# ime5_target_db register map
Vendor: Texas Instruments
Peripheral module from a debugger description file (folder iva2_arp32).
Address unit: 16 bits
Registers are 32-bit, access per field, reset 0x0 unless marked. A register's access mark holds for its fields unless they carry their own. Offsets are as the file gives them; lines under a group give offsets from that group; [hi:lo] are bit positions; {n}, {i} and the like mark numbered series; 'fields as' and 'values as' point back to an identical list; <NAME> marks a mode.

## IME5 (part 1 of 3) — ipxact12_to_ccs_generated
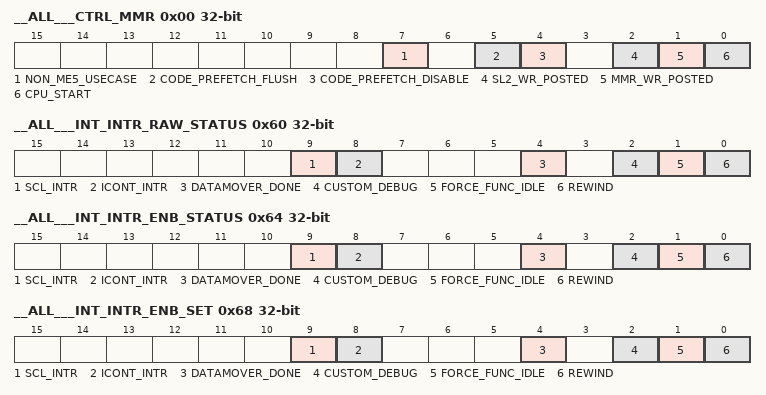
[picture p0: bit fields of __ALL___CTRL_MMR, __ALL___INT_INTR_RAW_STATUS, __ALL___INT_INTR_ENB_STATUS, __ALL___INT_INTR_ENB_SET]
0x00 __ALL___CTRL_MMR — Holds the various system control registers.
  [7] NON_ME5_USECASE rw — Set to 1 to indicate Non ME5 usecase. In this mode, the HW engines for motion estimation will not be usable. Set to 0 for ME5 usecase. In this mode, the HW engines for motion estimation are active. The Host config master interface will not be usable. In other words, in this mode, ME5 cpu will not be able to write/read MMR/config registers that are external to ME5. SL2 data can still be accessed.
  [5] CODE_PREFETCH_FLUSH rw — Flush code prefetch from SL2 space. Auto cleared to 0.
  [4] CODE_PREFETCH_DISABLE rw — Disable code prefetch from SL2 space.
  [2] SL2_WR_POSTED rw — When set, Posted SL2 writes from CPU will be enabled. When cleared, all SL2 writes from CPU are performed as non-posted writes.
  [1] MMR_WR_POSTED rw — When set, Posted MMR writes from CPU will be enabled. When cleared, all MMR writes from CPU are performed as non-posted writes.
  [0] CPU_START rw — When Set, Indicates that ME5 CPU is enabled to execute (out of reset). When low, indicates that ME5 CPU is in reset. (When low, it should remain low for atleast 4 clock period to reset cpu)
0x04 __ALL___ME5_INTR_OUTPUT rw — Generates interrupt to SCL module. Corresponding bitfield is to be set to generate interrupt. The bitfield is self cleared on generating interrupt.
  [0] SCL_INTR — Generates Interrupt to Scalar.
0x40 __ALL___DM_SRC rw — DataMover Units Source Address register. Address should be a multiple of 4.
  [31:0] SRC — Specifies the data Source.
0x44 __ALL___DM_DST rw — DataMover units Destination Address register. Address should be a multiple of 4.
  [31:0] DST — Specifies the data Destination.
0x48 __ALL___DM_ByteCnt — DataMover units ByteCount register. Specifies the number of bytes to be transfered from Source address to Destination address. This should be a mulyiple of 4. Write to this register triggers data transfer.
  [15:0] ByteCount rw — Specifies the size of data transfer (in Bytes).
0x60 __ALL___INT_INTR_RAW_STATUS rw — This provides the status of the interrupt sources generating interrupt to ME5-ARP32, irrespective of enable bit. Write 1 to set the interrupt in Software (for test/debug).
  [9] SCL_INTR — Interrupt from SCL.
  [8] ICONT_INTR — Interrupt from ICONT.
  [4] DATAMOVER_DONE — DataMover transfer completion.
  [2] CUSTOM_DEBUG — Custom Debug event detected by HW.
  [1] FORCE_FUNC_IDLE — Abort or channel switch after rewind condition.
  [0] REWIND — Rewind process complete.
0x64 __ALL___INT_INTR_ENB_STATUS rw — This provides the status of the interrupt sources generating interrupt to ICONT, enabled to interrupt. Write 1 to clear the interrupt in Software.
  fields as __ALL___INT_INTR_RAW_STATUS
0x68 __ALL___INT_INTR_ENB_SET rw — Enables the corresponding interrupt source to generate interrupt to ICONT. Write 1 to set the corresponding interrupt enable bit.
  fields as __ALL___INT_INTR_RAW_STATUS
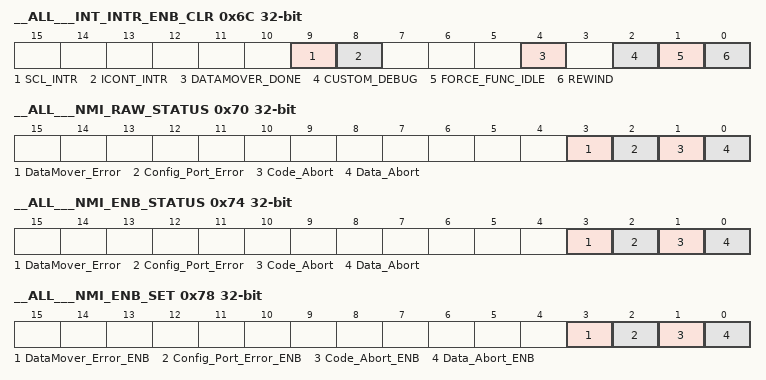
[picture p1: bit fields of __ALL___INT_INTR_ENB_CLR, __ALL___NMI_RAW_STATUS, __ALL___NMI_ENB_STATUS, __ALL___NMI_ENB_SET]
0x6C __ALL___INT_INTR_ENB_CLR rw — Enables the corresponding interrupt source to generate interrupt to ICONT. Write 1 to Clear the corresponding interrupt enable bit.
  fields as __ALL___INT_INTR_RAW_STATUS
0x70 __ALL___NMI_RAW_STATUS — This provides the status of the ICONT NMI sources, irrespective of enable bit. Write 1 to set the interrupt in Software (for test/debug).
  [3] DataMover_Error rw — Indicates if the previous data transfer completed with an ocp error.
  [2] Config_Port_Error rw — Indicates error response on Config master port.
  [1] Code_Abort rw — CPU Code access to Reserved space. ICONT_NMI_ABORT_ADDR logs the access address.
  [0] Data_Abort rw — CPU data access to Reserved space. ICONT_NMI_ABORT_ADDR logs the access address.
0x74 __ALL___NMI_ENB_STATUS — This provides the status of the ICONT NMI interrupt sources enabled to interrupt. Write 1 to clear the interrupt in Software.
  [3] DataMover_Error rw — Indicates if the previous data transfer completed with an ocp error.
  [2] Config_Port_Error rw — Indicates error response on Config master port.
  [1] Code_Abort rw — CPU code access to Reserved space. ICONT_NMI_ABORT_ADDR logs the access address.
  [0] Data_Abort rw — CPU data access to Reserved space. ICONT_NMI_ABORT_ADDR logs the access address.
0x78 __ALL___NMI_ENB_SET — Enables the corresponding interrupt source to generate interrupt. Write 1 to set the corresponding interrupt enable bit.
  [3] DataMover_Error_ENB rw — Indicates if the previous data transfer completed with an ocp error.
  [2] Config_Port_Error_ENB rw
  [1] Code_Abort_ENB rw
  [0] Data_Abort_ENB rw
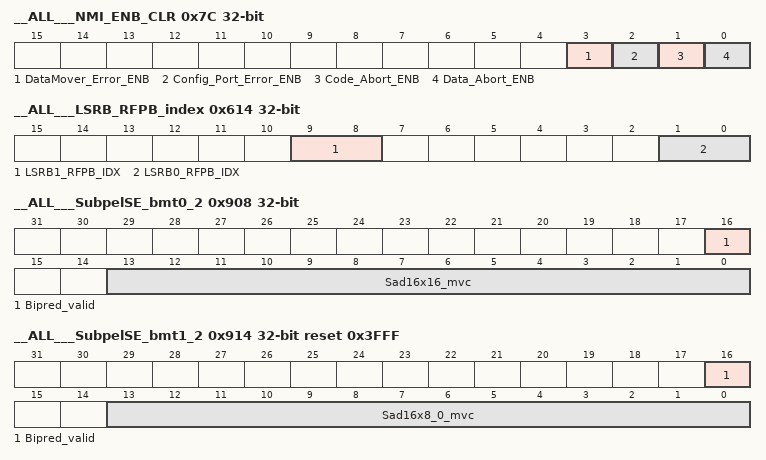
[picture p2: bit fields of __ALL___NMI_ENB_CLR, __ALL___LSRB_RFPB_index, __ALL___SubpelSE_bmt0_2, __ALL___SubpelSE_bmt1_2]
0x7C __ALL___NMI_ENB_CLR — Enables the corresponding interrupt source to generate interrupt. Write 1 to Clear the corresponding interrupt enable bit.
  fields as __ALL___NMI_ENB_SET
0x80 __ALL___NMI_ABORT_ADDR ro — Logs the Address that resulted in the T16Core Data or Code abort condition.
  [31:0] Address
0x100 __ALL___PSE_bmt0_0 rw — This register contains motion vector for best 16x16 partition
  [31:0] mvy_mvx — Motion vector
0x104 __ALL___PSE_bmt0_1 reset 0xFFFF — This register contains SAD for best 16x16 partition
  [15:0] Sad16x16 rw — SAD Value
0x108 __ALL___PSE_bmt0_2 — This register contains Motion Vector Cost for best 16x16 partition
  [13:0] Sad16x16_mvc rw — Motion vector Cost
0x10C __ALL___PSE_bmt1_0 rw — This register contains motion vector for best top 16x8 partition
  [31:0] mvy_mvx — Motion vector
0x110 __ALL___PSE_bmt1_1 reset 0xFFFF — This register contains SAD for best top 16x8 partition
  [15:0] Sad16x8_0 rw — SAD Value
0x114 __ALL___PSE_bmt1_2 reset 0x3FFF
  [13:0] Sad16x8_0_mvc rw — Motion vector Cost
0x118 __ALL___PSE_bmt2_0 rw — This register contains motion vector for best bottom 16x8 partition
  [31:0] mvy_mvx — Motion vector
0x11C __ALL___PSE_bmt2_1 reset 0xFFFF — This register contains SAD for best bottom 16x8 partition
  [15:0] Sad16x8_1 rw — SAD Value
0x120 __ALL___PSE_bmt2_2 reset 0x3FFF
  [13:0] Sad16x8_1_mvc rw — Motion vector Cost
0x124 __ALL___PSE_bmt3_0 rw — This register contains motion vector for best left 8x16 partition
  [31:0] mvy_mvx — Motion vector
0x128 __ALL___PSE_bmt3_1 reset 0xFFFF — This register contains SAD for best left 8x16 partition
  [15:0] Sad8x16_0 rw — SAD Value
0x12C __ALL___PSE_bmt3_2 reset 0x3FFF
  [13:0] Sad8x16_0_mvc rw — Motion vector Cost
0x130 __ALL___PSE_bmt4_0 rw — This register contains motion vector for best right 8x16 partition
  [31:0] mvy_mvx — Motion vector
0x134 __ALL___PSE_bmt4_1 reset 0xFFFF — This register contains SAD for best right 8x16 partition
  [15:0] Sad8x16_1 rw — SAD Value
0x138 __ALL___PSE_bmt4_2 reset 0x3FFF
  [13:0] Sad8x16_1_mvc rw — Motion vector Cost
0x13C __ALL___PSE_bmt5_0 rw — This register contains motion vector for best top left 8x8 partition
  [31:0] mvy_mvx — Motion vector
0x140 __ALL___PSE_bmt5_1 reset 0xFFFF — This register contains SAD for best top left 8x8 partition
  [15:0] Sad8x8_0 rw — SAD Value
{0x108+0xC*i} __ALL___PSE_bmt{i}_2 reset 0x3FFF (i=5..8)
  [13:0] Sad8x8_{i-5}_mvc rw — Motion vector Cost
0x148 __ALL___PSE_bmt6_0 rw — This register contains motion vector for best top right 8x8 partition
  [31:0] mvy_mvx — Motion vector
0x14C __ALL___PSE_bmt6_1 reset 0xFFFF — This register contains SAD for best top right 8x8 partition
  [15:0] Sad8x8_1 rw — SAD Value
0x154 __ALL___PSE_bmt7_0 rw — This register contains motion vector for best bottom leftt 8x8 partition
  [31:0] mvy_mvx — Motion vector
0x158 __ALL___PSE_bmt7_1 reset 0xFFFF — This register contains SAD for best bottom leftt 8x8 partition
  [15:0] Sad8x8_2 rw — SAD Value
0x160 __ALL___PSE_bmt8_0 rw — This register contains motion vector for best bottomright 8x8 partition
  [31:0] mvy_mvx — Motion vector
0x164 __ALL___PSE_bmt8_1 reset 0xFFFF — This register contains SAD for best bottomright 8x8 partition
  [15:0] Sad8x8_3 rw — SAD Value
{0x100+0xC*i} __ALL___PSE_bmt{i}_0 rw (i=9..11) — This register contains motion vector for best next best 16x16 partition
  [31:0] mvy_mvx — Motion vector
{0x104+0xC*i} __ALL___PSE_bmt{i}_1 reset 0xFFFF (i=9..11) — This register contains SAD for best next best 16x16 partition
  [15:0] Sad16x16_{i-8} rw — SAD Value
{0x108+0xC*i} __ALL___PSE_bmt{i}_2 reset 0x3FFF (i=9..11)
  [13:0] Sad16x16_{i-8}_mvc rw — Motion vector Cost
0x200 __ALL___PSE_SHADOWbmt0_0 rw — This register contains motion vector for best 16x16 partition
  [31:0] mvy_mvx — Motion vector
0x204 __ALL___PSE_SHADOWbmt0_1 reset 0xFFFF — This register contains SAD for best 16x16 partition
  [15:0] Sad16x16 rw — SAD Value
0x208 __ALL___PSE_SHADOWbmt0_2 — This register contains Motion Vector Cost for best 16x16 partition
  [13:0] Sad16x16_mvc rw — Motion vector Cost
0x20C __ALL___PSE_SHADOWbmt1_0 rw — This register contains motion vector for best top 16x8 partition
  [31:0] mvy_mvx — Motion vector
0x210 __ALL___PSE_SHADOWbmt1_1 reset 0xFFFF — This register contains SAD for best top 16x8 partition
  [15:0] Sad16x8_0 rw — SAD Value
0x214 __ALL___PSE_SHADOWbmt1_2 reset 0x3FFF
  [13:0] Sad16x8_0_mvc rw — Motion vector Cost
0x218 __ALL___PSE_SHADOWbmt2_0 rw — This register contains motion vector for best bottom 16x8 partition
  [31:0] mvy_mvx — Motion vector
0x21C __ALL___PSE_SHADOWbmt2_1 reset 0xFFFF — This register contains SAD for best bottom 16x8 partition
  [15:0] Sad16x8_1 rw — SAD Value
0x220 __ALL___PSE_SHADOWbmt2_2 reset 0x3FFF
  [13:0] Sad16x8_1_mvc rw — Motion vector Cost
0x224 __ALL___PSE_SHADOWbmt3_0 rw — This register contains motion vector for best left 8x16 partition
  [31:0] mvy_mvx — Motion vector
0x228 __ALL___PSE_SHADOWbmt3_1 reset 0xFFFF — This register contains SAD for best left 8x16 partition
  [15:0] Sad8x16_0 rw — SAD Value
0x22C __ALL___PSE_SHADOWbmt3_2 reset 0x3FFF
  [13:0] Sad8x16_0_mvc rw — Motion vector Cost
0x230 __ALL___PSE_SHADOWbmt4_0 rw — This register contains motion vector for best right 8x16 partition
  [31:0] mvy_mvx — Motion vector
0x234 __ALL___PSE_SHADOWbmt4_1 reset 0xFFFF — This register contains SAD for best right 8x16 partition
  [15:0] Sad8x16_1 rw — SAD Value
0x238 __ALL___PSE_SHADOWbmt4_2 reset 0x3FFF
  [13:0] Sad8x16_1_mvc rw — Motion vector Cost
0x23C __ALL___PSE_SHADOWbmt5_0 rw — This register contains motion vector for best top left 8x8 partition
  [31:0] mvy_mvx — Motion vector
0x240 __ALL___PSE_SHADOWbmt5_1 reset 0xFFFF — This register contains SAD for best top left 8x8 partition
  [15:0] Sad8x8_0 rw — SAD Value
{0x208+0xC*i} __ALL___PSE_SHADOWbmt{i}_2 reset 0x3FFF (i=5..8)
  [13:0] Sad8x8_{i-5}_mvc rw — Motion vector Cost
0x248 __ALL___PSE_SHADOWbmt6_0 rw — This register contains motion vector for best top right 8x8 partition
  [31:0] mvy_mvx — Motion vector
0x24C __ALL___PSE_SHADOWbmt6_1 reset 0xFFFF — This register contains SAD for best top right 8x8 partition
  [15:0] Sad8x8_1 rw — SAD Value
0x254 __ALL___PSE_SHADOWbmt7_0 rw — This register contains motion vector for best bottom leftt 8x8 partition
  [31:0] mvy_mvx — Motion vector
0x258 __ALL___PSE_SHADOWbmt7_1 reset 0xFFFF — This register contains SAD for best bottom leftt 8x8 partition
  [15:0] Sad8x8_2 rw — SAD Value
0x260 __ALL___PSE_SHADOWbmt8_0 rw — This register contains motion vector for best bottomright 8x8 partition
  [31:0] mvy_mvx — Motion vector
0x264 __ALL___PSE_SHADOWbmt8_1 reset 0xFFFF — This register contains SAD for best bottomright 8x8 partition
  [15:0] Sad8x8_3 rw — SAD Value
{0x200+0xC*i} __ALL___PSE_SHADOWbmt{i}_0 rw (i=9..11) — This register contains motion vector for best next best 16x16 partition
  [31:0] mvy_mvx — Motion vector
{0x204+0xC*i} __ALL___PSE_SHADOWbmt{i}_1 reset 0xFFFF (i=9..11) — This register contains SAD for best next best 16x16 partition
  [15:0] Sad16x16_{i-8} rw — SAD Value
{0x208+0xC*i} __ALL___PSE_SHADOWbmt{i}_2 reset 0x3FFF (i=9..11)
  [13:0] Sad16x16_{i-8}_mvc rw — Motion vector Cost
0x500 __ALL___VSE_bmt0_0 rw — This register contains motion vector for best 16x16 partition
  [31:0] mvy_mvx — Motion vector
0x504 __ALL___VSE_bmt0_1 reset 0xFFFF — This register contains SAD for best 16x16 partition
  [15:0] Sad16x16 rw — SAD Value
0x508 __ALL___VSE_bmt0_2 — This register contains Motion Vector Cost for best 16x16 partition
  [13:0] Sad16x16_mvc rw — Motion vector Cost
0x50C __ALL___VSE_bmt1_0 rw — This register contains motion vector for best top 16x8 partition
  [31:0] mvy_mvx — Motion vector
0x510 __ALL___VSE_bmt1_1 reset 0xFFFF — This register contains SAD for best top 16x8 partition
  [15:0] Sad16x8_0 rw — SAD Value
0x514 __ALL___VSE_bmt1_2 reset 0x3FFF
  [13:0] Sad16x8_0_mvc rw — Motion vector Cost
0x518 __ALL___VSE_bmt2_0 rw — This register contains motion vector for best bottom 16x8 partition
  [31:0] mvy_mvx — Motion vector
0x51C __ALL___VSE_bmt2_1 reset 0xFFFF — This register contains SAD for best bottom 16x8 partition
  [15:0] Sad16x8_1 rw — SAD Value
0x520 __ALL___VSE_bmt2_2 reset 0x3FFF
  [13:0] Sad16x8_1_mvc rw — Motion vector Cost
0x524 __ALL___VSE_bmt3_0 rw — This register contains motion vector for best left 8x16 partition
  [31:0] mvy_mvx — Motion vector
0x528 __ALL___VSE_bmt3_1 reset 0xFFFF — This register contains SAD for best left 8x16 partition
  [15:0] Sad8x16_0 rw — SAD Value
0x52C __ALL___VSE_bmt3_2 reset 0x3FFF
  [13:0] Sad8x16_0_mvc rw — Motion vector Cost
0x530 __ALL___VSE_bmt4_0 rw — This register contains motion vector for best right 8x16 partition
  [31:0] mvy_mvx — Motion vector
0x534 __ALL___VSE_bmt4_1 reset 0xFFFF — This register contains SAD for best right 8x16 partition
  [15:0] Sad8x16_1 rw — SAD Value
0x538 __ALL___VSE_bmt4_2 reset 0x3FFF
  [13:0] Sad8x16_1_mvc rw — Motion vector Cost
0x53C __ALL___VSE_bmt5_0 rw — This register contains motion vector for best top left 8x8 partition
  [31:0] mvy_mvx — Motion vector
0x540 __ALL___VSE_bmt5_1 reset 0xFFFF — This register contains SAD for best top left 8x8 partition
  [15:0] Sad8x8_0 rw — SAD Value
{0x508+0xC*i} __ALL___VSE_bmt{i}_2 reset 0x3FFF (i=5..8)
  [13:0] Sad8x8_{i-5}_mvc rw — Motion vector Cost
0x548 __ALL___VSE_bmt6_0 rw — This register contains motion vector for best top right 8x8 partition
  [31:0] mvy_mvx — Motion vector
0x54C __ALL___VSE_bmt6_1 reset 0xFFFF — This register contains SAD for best top right 8x8 partition
  [15:0] Sad8x8_1 rw — SAD Value
0x554 __ALL___VSE_bmt7_0 rw — This register contains motion vector for best bottom leftt 8x8 partition
  [31:0] mvy_mvx — Motion vector
0x558 __ALL___VSE_bmt7_1 reset 0xFFFF — This register contains SAD for best bottom leftt 8x8 partition
  [15:0] Sad8x8_2 rw — SAD Value
0x560 __ALL___VSE_bmt8_0 rw — This register contains motion vector for best bottomright 8x8 partition
  [31:0] mvy_mvx — Motion vector
0x564 __ALL___VSE_bmt8_1 reset 0xFFFF — This register contains SAD for best bottomright 8x8 partition
  [15:0] Sad8x8_3 rw — SAD Value
{0x500+0xC*i} __ALL___VSE_bmt{i}_0 rw (i=9..14) — This register contains motion vector for best next best 16x16 partition
  [31:0] mvy_mvx — Motion vector
{0x504+0xC*i} __ALL___VSE_bmt{i}_1 reset 0xFFFF (i=9..14) — This register contains SAD for best next best 16x16 partition
  [15:0] Sad16x16_{i-8} rw — SAD Value
{0x508+0xC*i} __ALL___VSE_bmt{i}_2 reset 0x3FFF (i=9..14)
  [13:0] Sad16x16_{i-8}_mvc rw — Motion vector Cost
0x5B4 __ALL___VSE_SC_Extra rw — Additional Search centre register
  [31:0] mvy_mvx — Motion vector
0x600 __ALL___LSRB0_Base rw — LSRB0 Base address
  [31:0] mvy_mvx — Motion vector
0x604 __ALL___LSRB1_Base rw reset 0x1 — LSRB1 Base address
  [31:0] mvy_mvx — Motion vector
0x608 __ALL___LSRB0_Valid_offsets ro (reset mask 0xC0C0C0C0) — LSRB0 Valid offset for valid area checks
0x60C __ALL___LSRB1_Valid_offsets ro (reset mask 0xC0C0C0C0) — LSRB1 Valid offset for valid area checks
0x610 __ALL___LSRB_reference_mv rw — LSRB reference motion vector for load lsrb
  [31:0] mvy_mvx — Motion vector
0x614 __ALL___LSRB_RFPB_index — LSRB_RFPB_index
  [9:8] LSRB1_RFPB_IDX rw, [1:0] LSRB0_RFPB_IDX rw
0x900 __ALL___SubpelSE_bmt0_0 rw — This register contains motion vector for best 16x16 partition
  [31:0] mvy_mvx — Motion vector
0x904 __ALL___SubpelSE_bmt0_1 reset 0xFFFF — This register contains SAD for best 16x16 partition
  [16:0] Sad16x16 rw — SAD Value
0x908 __ALL___SubpelSE_bmt0_2 — This register contains Motion Vector Cost for best 16x16 partition
  [16] Bipred_valid rw — Bipred valid bit
  [13:0] Sad16x16_mvc rw — Motion vector Cost
0x90C __ALL___SubpelSE_bmt1_0 rw — This register contains motion vector for best top 16x8 partition
  [31:0] mvy_mvx — Motion vector
0x910 __ALL___SubpelSE_bmt1_1 reset 0xFFFF — This register contains SAD for best top 16x8 partition
  [16:0] Sad16x8_0 rw — SAD Value
0x914 __ALL___SubpelSE_bmt1_2 reset 0x3FFF — This register contains Motion Vector Cost for best top 16x8 partition
  [16] Bipred_valid rw — Bipred valid bit
  [13:0] Sad16x8_0_mvc rw — Motion vector Cost
0x918 __ALL___SubpelSE_bmt2_0 rw — This register contains motion vector for best bottom 16x8 partition
  [31:0] mvy_mvx — Motion vector
0x91C __ALL___SubpelSE_bmt2_1 reset 0xFFFF — This register contains SAD for best bottom 16x8 partition
  [16:0] Sad16x8_1 rw — SAD Value
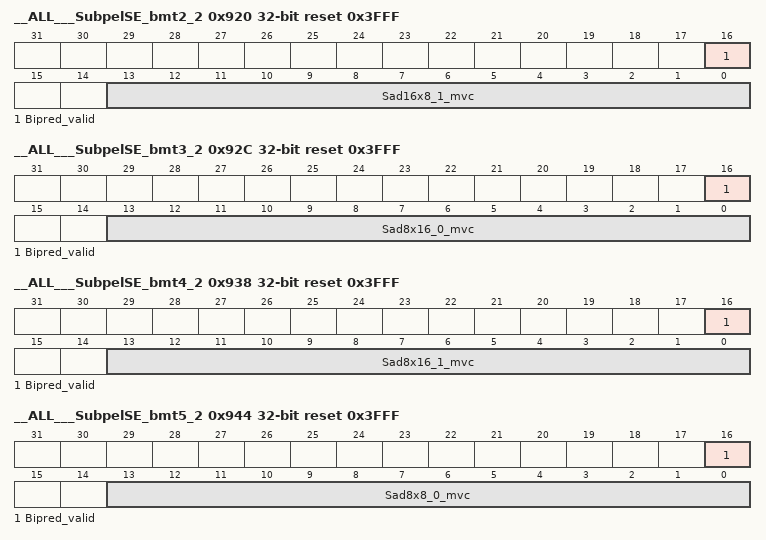
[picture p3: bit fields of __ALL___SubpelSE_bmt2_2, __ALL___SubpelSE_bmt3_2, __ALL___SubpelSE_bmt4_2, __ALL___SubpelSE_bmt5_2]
0x920 __ALL___SubpelSE_bmt2_2 reset 0x3FFF — This register contains Motion Vector Cost for best bottom 16x8 partition
  [16] Bipred_valid rw — Bipred valid bit
  [13:0] Sad16x8_1_mvc rw — Motion vector Cost
0x924 __ALL___SubpelSE_bmt3_0 rw — This register contains motion vector for best left 8x16 partition
  [31:0] mvy_mvx — Motion vector
0x928 __ALL___SubpelSE_bmt3_1 reset 0xFFFF — This register contains SAD for best left 8x16 partition
  [16:0] Sad8x16_0 rw — SAD Value
0x92C __ALL___SubpelSE_bmt3_2 reset 0x3FFF — This register contains Motion Vector Cost for best left 8x16 partition
  [16] Bipred_valid rw — Bipred valid bit
  [13:0] Sad8x16_0_mvc rw — Motion vector Cost
0x930 __ALL___SubpelSE_bmt4_0 rw — This register contains motion vector for best right 8x16 partition
  [31:0] mvy_mvx — Motion vector
0x934 __ALL___SubpelSE_bmt4_1 reset 0xFFFF — This register contains SAD for best right 8x16 partition
  [16:0] Sad8x16_1 rw — SAD Value
0x938 __ALL___SubpelSE_bmt4_2 reset 0x3FFF — This register contains Motion Vector Cost for best right 8x16 partition
  [16] Bipred_valid rw — Bipred valid bit
  [13:0] Sad8x16_1_mvc rw — Motion vector Cost
0x93C __ALL___SubpelSE_bmt5_0 rw — This register contains motion vector for best top left 8x8 partition
  [31:0] mvy_mvx — Motion vector
0x940 __ALL___SubpelSE_bmt5_1 reset 0xFFFF — This register contains SAD for best top left 8x8 partition
  [16:0] Sad8x8_0 rw — SAD Value
0x944 __ALL___SubpelSE_bmt5_2 reset 0x3FFF — This register contains Motion Vector Cost for best top left 8x8 partition
  [16] Bipred_valid rw — Bipred valid bit
  [13:0] Sad8x8_0_mvc rw — Motion vector Cost
0x948 __ALL___SubpelSE_bmt6_0 rw — This register contains motion vector for best top right 8x8 partition
  [31:0] mvy_mvx — Motion vector
0x94C __ALL___SubpelSE_bmt6_1 reset 0xFFFF — This register contains SAD for best top right 8x8 partition
  [16:0] Sad8x8_1 rw — SAD Value
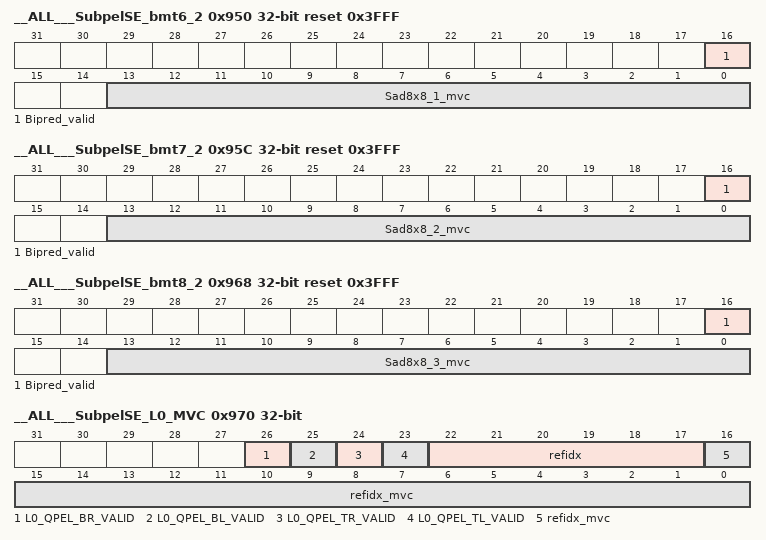
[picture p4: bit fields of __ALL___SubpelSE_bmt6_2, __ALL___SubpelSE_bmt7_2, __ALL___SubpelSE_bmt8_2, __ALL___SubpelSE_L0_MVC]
0x950 __ALL___SubpelSE_bmt6_2 reset 0x3FFF — This register contains Motion Vector Cost for best top right 8x8 partition
  [16] Bipred_valid rw — Bipred valid bit
  [13:0] Sad8x8_1_mvc rw — Motion vector Cost
0x954 __ALL___SubpelSE_bmt7_0 rw — This register contains motion vector for best bottom leftt 8x8 partition
  [31:0] mvy_mvx — Motion vector
0x958 __ALL___SubpelSE_bmt7_1 reset 0xFFFF — This register contains SAD for best bottom leftt 8x8 partition
  [16:0] Sad8x8_2 rw — SAD Value
0x95C __ALL___SubpelSE_bmt7_2 reset 0x3FFF — This register contains Motion Vector Cost for best bottom leftt 8x8 partition
  [16] Bipred_valid rw — Bipred valid bit
  [13:0] Sad8x8_2_mvc rw — Motion vector Cost
0x960 __ALL___SubpelSE_bmt8_0 rw — This register contains motion vector for best bottomright 8x8 partition
  [31:0] mvy_mvx — Motion vector
0x964 __ALL___SubpelSE_bmt8_1 reset 0xFFFF — This register contains SAD for best bottomright 8x8 partition
  [16:0] Sad8x8_3 rw — SAD Value
0x968 __ALL___SubpelSE_bmt8_2 reset 0x3FFF — This register contains Motion Vector Cost for best bottomright 8x8 partition
  [16] Bipred_valid rw — Bipred valid bit
  [13:0] Sad8x8_3_mvc rw — Motion vector Cost
0x96C __ALL___SubpelSE_L0_MV rw — This register contains motion vector of winner q-pel plane
  [31:0] mvy_mvx — Motion vector
0x970 __ALL___SubpelSE_L0_MVC — This register contains motion vector of winner q-pel plane motion vector
  [26] L0_QPEL_BR_VALID rw — L0 MV is valid
  [25] L0_QPEL_BL_VALID rw — L0 MV is valid
  [24] L0_QPEL_TR_VALID rw — L0 MV is valid
  [23] L0_QPEL_TL_VALID rw — L0 MV is valid
  [22:17] refidx rw — LO referecne Idx
  [16:0] refidx_mvc rw — Motion vector Cost
0x974 __ALL___HPEL_SC_EXTRA rw — This register contains motion vector of search centre for hpel calculation
  [31:0] mvy_mvx — Motion vector
0x978 __ALL___QPEL_SC_EXTRA rw — This register contains motion vector of search centre for qpel calculation
  [31:0] mvy_mvx — Motion vector
0x97C __ALL___WINNER_MV_STATS rw — This register contains motion vector after Qpel for Statistic collection
  [31:0] mvy_mvx — Motion vector for Statistic collection. Updated after searchQpel instruction if the update_statistics flag is set. This motion vector will be used for updating the statistics during write output instruction. Also note that USE_FOR_MVSTAT in RF_CTRL_REG0_RFPB1 should also be set for this register to be updated.
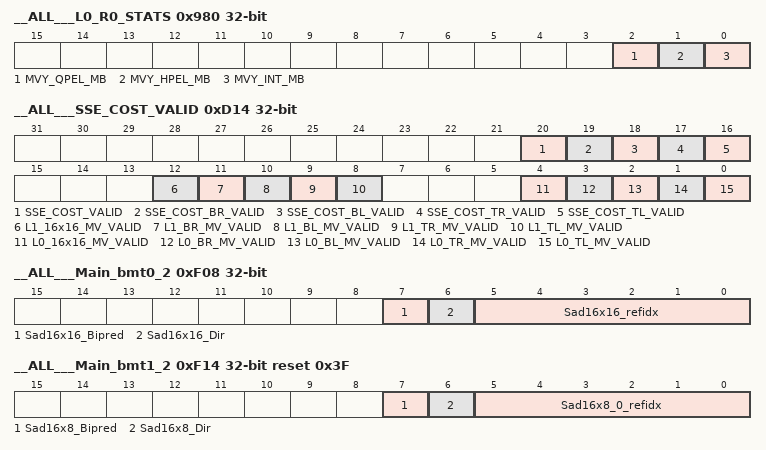
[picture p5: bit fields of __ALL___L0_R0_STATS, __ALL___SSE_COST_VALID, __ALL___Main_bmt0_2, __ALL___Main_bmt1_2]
0x980 __ALL___L0_R0_STATS rw — This register contains Statistics information for winner L0 R0 motion vector
  [2] MVY_QPEL_MB — This bit field set when L0 R0 winner motion vector's Y component is QPEL. This bit is updated only after searchQpel instruction if the update_statistics flag is set. Note that this bit is updated only during L0 direction and when the reference index is 0
  [1] MVY_HPEL_MB — This bit field set when L0 R0 winner motion vector's Y component is HPEL. This bit is updated only after searchQpel instruction if the update_statistics flag is set. Note that this bit is updated only during L0 direction and when the reference index is 0
  [0] MVY_INT_MB — This bit field set when L0 R0 winner motion vector's Y component is integer. This bit is updated only after searchQpel instruction if the update_statistics flag is set. Note that this bit is updated only during L0 direction and when the reference index is 0
0xD00 __ALL___SSE_Cost16x16 reset 0xFFFF — This register contains cost of 16x16 partition at skip mv position
  [15:0] SSE_Cost16x16 rw — 16x16 SAD cost
0xD04 __ALL___SSE_Cost_TL8x8 reset 0x3FFF — This register contains cost of TL 8x8 partition at skip mv position
  [13:0] SSE_Cost_TL8x8 rw — 8x8 TL SAD cost
0xD08 __ALL___SSE_Cost_TR8x8 reset 0x3FFF — This register contains cost of TR 8x8 partition at skip mv position
  [13:0] SSE_Cost_TR8x8 rw — 8x8 TR SAD cost
0xD0C __ALL___SSE_Cost_BL8x8 reset 0x3FFF — This register contains cost of BL 8x8 partition at skip mv position
  [13:0] SSE_Cost_BL8x8 rw — 8x8 BL SAD cost
0xD10 __ALL___SSE_Cost_BR8x8 reset 0x3FFF — This register contains cost of BR 8x8 partition at skip mv position
  [13:0] SSE_Cost_BR8x8 rw — 8x8 BR SAD cost
0xD14 __ALL___SSE_COST_VALID — This register contains valid bits for debug
  [20] SSE_COST_VALID rw
  [19] SSE_COST_BR_VALID rw — SSE cost valid
  [18] SSE_COST_BL_VALID rw — SSE cost valid
  [17] SSE_COST_TR_VALID rw — SSE cost valid
  [16] SSE_COST_TL_VALID rw — SSE cost valid
  [12] L1_16x16_MV_VALID rw — 16x16 valid
  [11] L1_BR_MV_VALID rw — BR Valid
  [10] L1_BL_MV_VALID rw — BL Valid
  [9] L1_TR_MV_VALID rw — TR valid
  [8] L1_TL_MV_VALID rw — TL valid
  [4] L0_16x16_MV_VALID rw — 16x16 valid
  [3] L0_BR_MV_VALID rw — BR Valid
  [2] L0_BL_MV_VALID rw — BL Valid
  [1] L0_TR_MV_VALID rw — TR valid
  [0] L0_TL_MV_VALID rw — TL valid
0xF00 __ALL___Main_bmt0_0 rw — This register contains motion vector for best 16x16 partition
  [31:0] mvy_mvx — Motion vector
0xF04 __ALL___Main_bmt0_1 reset 0xFFFF — This register contains Toal cost for best 16x16 partition
  [16:0] Sad16x16 rw — SAD Value
0xF08 __ALL___Main_bmt0_2 — This register contains ref index, Direction and bipred valid bits for best 16x16 partition
  [7] Sad16x16_Bipred rw — Bipred_valid
  [6] Sad16x16_Dir rw — Direction
  [5:0] Sad16x16_refidx rw — Ref index
0xF0C __ALL___Main_bmt1_0 rw — This register contains motion vector for best top 16x8 partition
  [31:0] mvy_mvx — Motion vector
0xF10 __ALL___Main_bmt1_1 reset 0xFFFF — This register contains Total Cost for best top 16x8 partition
  [16:0] Sad16x8_0 rw — SAD Value
0xF14 __ALL___Main_bmt1_2 reset 0x3F — This register contains ref index, Direction and bipred valid bits for best top 16x8 partition
  [7] Sad16x8_Bipred rw — Bipred_valid
  [6] Sad16x8_Dir rw — Direction
  [5:0] Sad16x8_0_refidx rw — Motion vector Cost
0xF18 __ALL___Main_bmt2_0 rw — This register contains motion vector for best bottom 16x8 partition
  [31:0] mvy_mvx — Motion vector
0xF1C __ALL___Main_bmt2_1 reset 0xFFFF — This register contains Total Cost for best bottom 16x8 partition
  [16:0] Sad16x8_1 rw — SAD Value
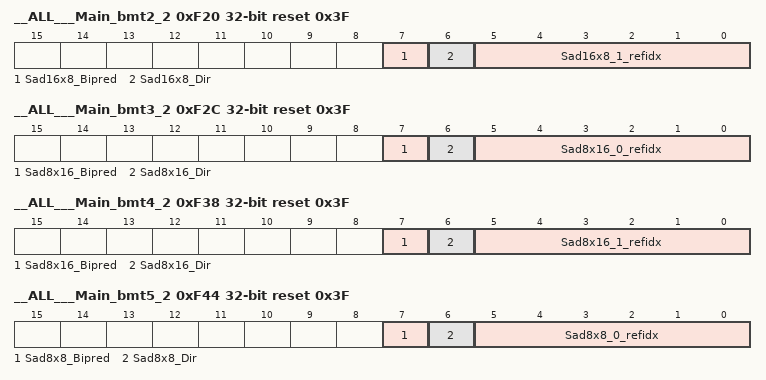
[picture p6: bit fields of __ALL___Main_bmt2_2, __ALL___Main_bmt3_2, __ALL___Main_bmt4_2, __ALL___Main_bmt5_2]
0xF20 __ALL___Main_bmt2_2 reset 0x3F — This register contains ref index, Direction and bipred valid bits for best bottom 16x8 partition
  [7] Sad16x8_Bipred rw — Bipred_valid
  [6] Sad16x8_Dir rw — Direction
  [5:0] Sad16x8_1_refidx rw — Motion vector Cost
0xF24 __ALL___Main_bmt3_0 rw — This register contains motion vector for best left 8x16 partition
  [31:0] mvy_mvx — Motion vector
0xF28 __ALL___Main_bmt3_1 reset 0xFFFF — This register contains Total Cost for best left 8x16 partition
  [16:0] Sad8x16_0 rw — SAD Value
0xF2C __ALL___Main_bmt3_2 reset 0x3F — This register contains ref index, Direction and bipred valid bits for best left 8x16 partition
  [7] Sad8x16_Bipred rw — Bipred_valid
  [6] Sad8x16_Dir rw — Direction
  [5:0] Sad8x16_0_refidx rw — Motion vector Cost
0xF30 __ALL___Main_bmt4_0 rw — This register contains motion vector for best right 8x16 partition
  [31:0] mvy_mvx — Motion vector
0xF34 __ALL___Main_bmt4_1 reset 0xFFFF — This register contains Total Cost for best right 8x16 partition
  [16:0] Sad8x16_1 rw — SAD Value
0xF38 __ALL___Main_bmt4_2 reset 0x3F — This register contains ref index, Direction and bipred valid bits for best right 8x16 partition
  [7] Sad8x16_Bipred rw — Bipred_valid
  [6] Sad8x16_Dir rw — Direction
  [5:0] Sad8x16_1_refidx rw — Motion vector Cost
0xF3C __ALL___Main_bmt5_0 rw — This register contains motion vector for best top left 8x8 partition
  [31:0] mvy_mvx — Motion vector
0xF40 __ALL___Main_bmt5_1 reset 0xFFFF — This register contains Total Cost for best top left 8x8 partition
  [16:0] Sad8x8_0 rw — SAD Value
0xF44 __ALL___Main_bmt5_2 reset 0x3F — This register contains ref index, Direction and bipred valid bits for best top left 8x8 partition
  [7] Sad8x8_Bipred rw — Bipred_valid
  [6] Sad8x8_Dir rw — Direction
  [5:0] Sad8x8_0_refidx rw — Motion vector Cost
0xF48 __ALL___Main_bmt6_0 rw — This register contains motion vector for best top right 8x8 partition
  [31:0] mvy_mvx — Motion vector
0xF4C __ALL___Main_bmt6_1 reset 0xFFFF — This register contains Total Cost for best top right 8x8 partition
  [16:0] Sad8x8_1 rw — SAD Value
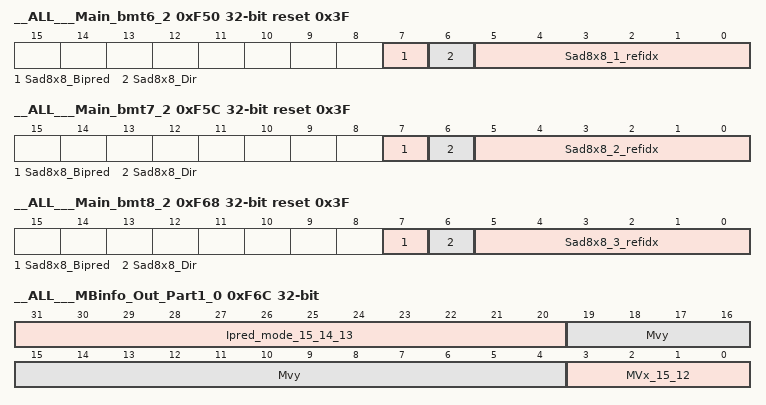
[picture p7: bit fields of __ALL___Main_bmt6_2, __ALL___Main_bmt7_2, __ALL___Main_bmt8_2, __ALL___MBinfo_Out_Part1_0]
0xF50 __ALL___Main_bmt6_2 reset 0x3F — This register contains ref index, Direction and bipred valid bits for best top right 8x8 partition
  [7] Sad8x8_Bipred rw — Bipred_valid
  [6] Sad8x8_Dir rw — Direction
  [5:0] Sad8x8_1_refidx rw — Motion vector Cost
0xF54 __ALL___Main_bmt7_0 rw — This register contains motion vector for best bottom leftt 8x8 partition
  [31:0] mvy_mvx — Motion vector
0xF58 __ALL___Main_bmt7_1 reset 0xFFFF — This register contains Total Cost for best bottom leftt 8x8 partition
  [16:0] Sad8x8_2 rw — SAD Value
0xF5C __ALL___Main_bmt7_2 reset 0x3F — This register contains ref index, Direction and bipred valid bits for best bottom leftt 8x8 partition
  [7] Sad8x8_Bipred rw — Bipred_valid
  [6] Sad8x8_Dir rw — Direction
  [5:0] Sad8x8_2_refidx rw — Motion vector Cost
0xF60 __ALL___Main_bmt8_0 rw — This register contains motion vector for best bottomright 8x8 partition
  [31:0] mvy_mvx — Motion vector
0xF64 __ALL___Main_bmt8_1 reset 0xFFFF — This register contains Total Cost for best bottomright 8x8 partition
  [16:0] Sad8x8_3 rw — SAD Value
0xF68 __ALL___Main_bmt8_2 reset 0x3F — This register contains ref index, Direction and bipred valid bits for best bottomright 8x8 partition
  [7] Sad8x8_Bipred rw — Bipred_valid
  [6] Sad8x8_Dir rw — Direction
  [5:0] Sad8x8_3_refidx rw — Motion vector Cost
0xF6C __ALL___MBinfo_Out_Part1_0 rw — Ipred_mode[15] ipred_mode[14], and ipred_mode[13]
  [31:20] Ipred_mode_15_14_13 — ipred_mode
  [19:4] Mvy
  [3:0] MVx_15_12 — MVx
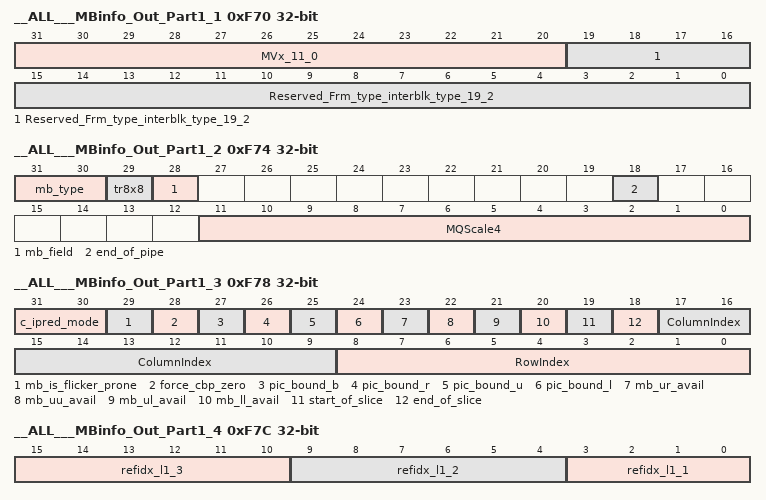
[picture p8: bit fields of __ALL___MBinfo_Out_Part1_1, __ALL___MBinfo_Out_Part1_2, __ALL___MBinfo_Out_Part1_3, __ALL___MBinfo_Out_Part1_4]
0xF70 __ALL___MBinfo_Out_Part1_1 rw — LSBs of MVx for TL inter mode winner
  [31:20] MVx_11_0 — MVx
  [19:0] Reserved_Frm_type_interblk_type_19_2 — Interblk_type
0xF74 __ALL___MBinfo_Out_Part1_2 rw — mb_type, tr8x8, qp values from ipe and other misc fields
  [31:30] mb_type
  [29] tr8x8
  [28] mb_field
  [18] end_of_pipe
  [11:0] MQScale4 — Modified Qscale4 by ME5
0xF78 __ALL___MBinfo_Out_Part1_3 rw — Cond_mbskip and other fields from IPE
  [31:30] c_ipred_mode
  [29] mb_is_flicker_prone — Valid for I-Frame in Encoder; 0 indicates Normal Function.1 indicates use MC output as Original in CALC Consumer : CALC; Producer : iCONT and IPE/ME?
  [28] force_cbp_zero — macroblock header data. This means ECD3 outputs right data for the first 64-bit of macroblock header, but the other parts of macroblock header data may be corrupted.
  [27] pic_bound_b
  [26] pic_bound_r
  [25] pic_bound_u
  [24] pic_bound_l
  [23] mb_ur_avail
  [22] mb_uu_avail
  [21] mb_ul_avail
  [20] mb_ll_avail
  [19] start_of_slice
  [18] end_of_slice
  [17:9] ColumnIndex
  [8:0] RowIndex
0xF7C __ALL___MBinfo_Out_Part1_4 rw — Referenece Index register1
  [15:10] refidx_l1_3, [9:4] refidx_l1_2, [3:0] refidx_l1_1
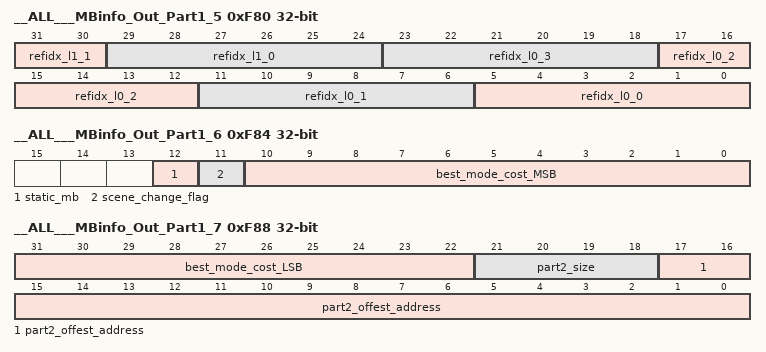
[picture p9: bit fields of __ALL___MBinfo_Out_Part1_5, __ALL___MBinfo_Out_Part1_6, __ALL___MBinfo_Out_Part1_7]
0xF80 __ALL___MBinfo_Out_Part1_5 rw — Referenece Index register2
  [31:30] refidx_l1_1, [29:24] refidx_l1_0, [6n+5:6n] refidx_l0_{n} (n=0..3)
0xF84 __ALL___MBinfo_Out_Part1_6 rw — MB statistic register
  [12] static_mb, [11] scene_change_flag, [10:0] best_mode_cost_MSB
0xF88 __ALL___MBinfo_Out_Part1_7 rw — Part2 Info register
  [31:22] best_mode_cost_LSB, [21:18] part2_size, [17:0] part2_offest_address
